# XHSC_HC32L12X register map
Vendor: XHSC Co.Ltd; Series: ARMCM0P; File version: 1.0
CPU: CM0P r0p0, little endian, no MPU, no FPU, 3 interrupt priority bits
Registers are 32-bit, read-write, reset 0x0 unless marked. A register's access mark holds for its fields unless they carry their own. Offsets are from the block's base; [hi:lo] are bit positions; 'fields as' and 'values as' point back to an identical list.

## DEBUG_ACTIVE
Base 0x40021838
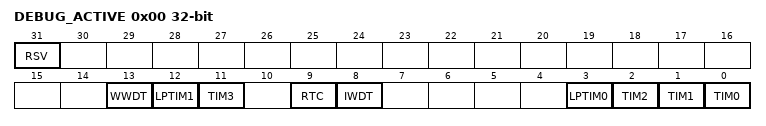
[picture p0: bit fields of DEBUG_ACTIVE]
0x00 DEBUG_ACTIVE (reset mask 0x3B0F)
  [31] RSV, [13] WWDT, [12] LPTIM1, [11] TIM3, [9] RTC, [8] IWDT, [3] LPTIM0, [2] TIM2, [1] TIM1, [0] TIM0

## DMAC
Base 0x40021000
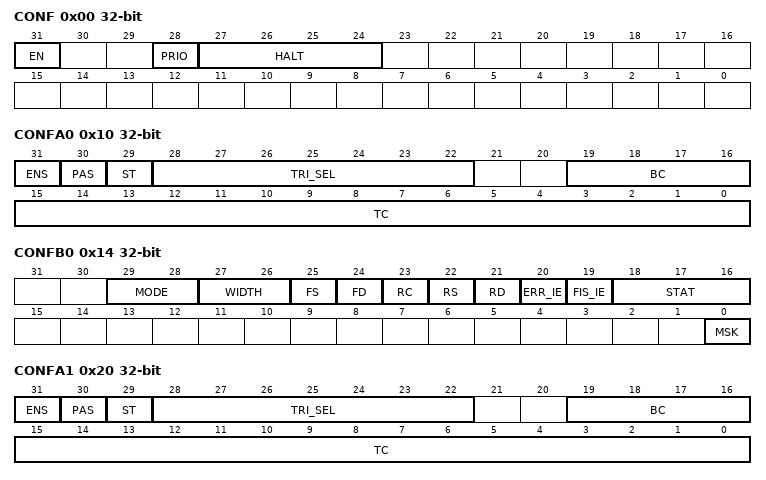
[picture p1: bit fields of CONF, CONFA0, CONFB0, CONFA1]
0x00 CONF
  [31] EN, [28] PRIO, [27:24] HALT
0x10 CONFA0
  [31] ENS, [30] PAS, [29] ST, [28:22] TRI_SEL, [19:16] BC, [15:0] TC
0x14 CONFB0
  [29:28] MODE, [27:26] WIDTH, [25] FS, [24] FD, [23] RC, [22] RS, [21] RD, [20] ERR_IE, [19] FIS_IE, [18:16] STAT, [0] MSK
0x18 SRCADR0
  [31:0] SRCADR
0x1C DSTADR0
  [31:0] DSTADR
0x20 CONFA1
  [31] ENS, [30] PAS, [29] ST, [28:22] TRI_SEL, [19:16] BC, [15:0] TC
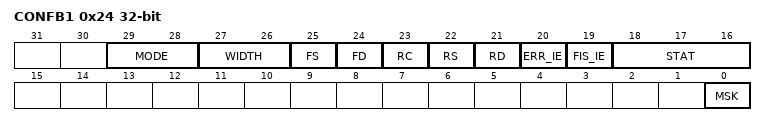
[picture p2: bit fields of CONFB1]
0x24 CONFB1
  fields as CONFB0
0x28 SRCADR
0x2C DSTADR

## FLASH
Base 0x40020000
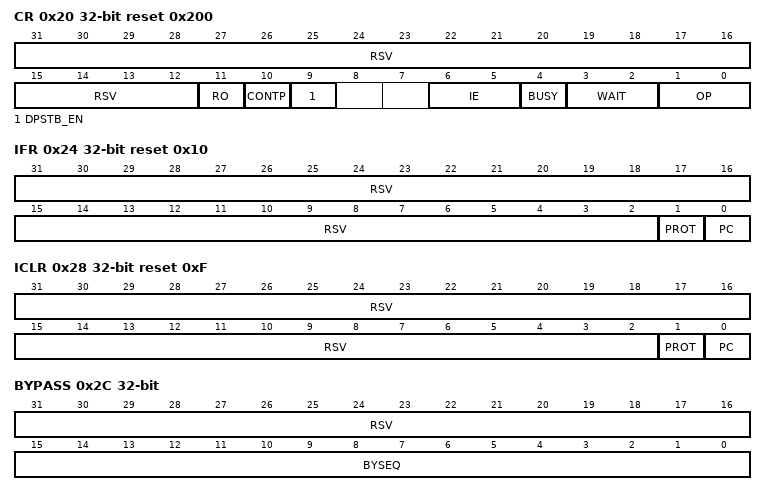
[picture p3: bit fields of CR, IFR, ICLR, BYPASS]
0x20 CR reset 0x200 (reset mask 0xFFF)
  [31:12] RSV, [11] RO, [10] CONTP, [9] DPSTB_EN, [6:5] IE, [4] BUSY ro, [3:2] WAIT, [1:0] OP
0x24 IFR ro reset 0x10 (reset mask 0x3)
  [31:2] RSV, [1] PROT, [0] PC
0x28 ICLR wo reset 0xF (reset mask 0xF)
  [31:2] RSV, [1] PROT, [0] PC
0x2C BYPASS wo (reset mask 0xFFFF)
  [31:16] RSV rw, [15:0] BYSEQ rw
0x30 SLOCK0
  [31:0] SLOCK
0x34 SLOCK1
  [31:0] SLOCK
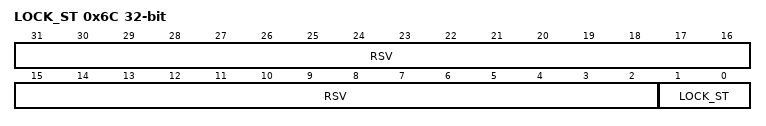
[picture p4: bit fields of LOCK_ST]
0x6C LOCK_ST ro (reset mask 0x3)
  [31:2] RSV rw, [1:0] LOCK_ST

## HSI2C
Base 0x4000BC00
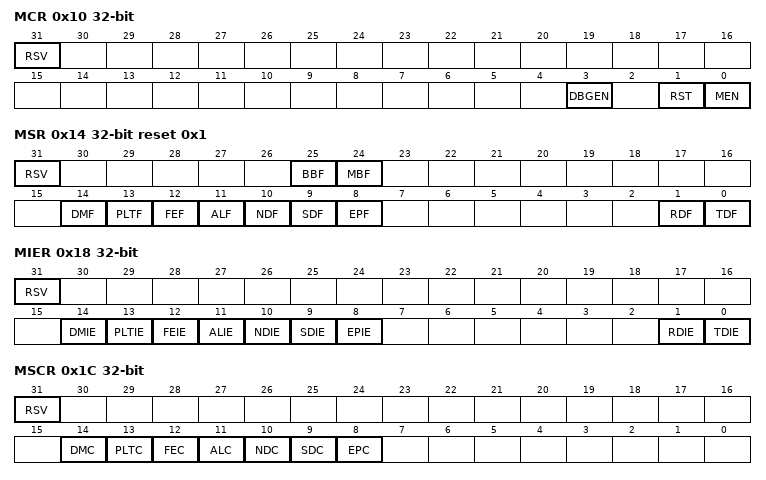
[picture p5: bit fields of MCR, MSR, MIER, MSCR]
0x10 MCR (reset mask 0xF)
  [31] RSV, [3] DBGEN, [1] RST, [0] MEN
0x14 MSR ro reset 0x1 (reset mask 0x0)
  [31] RSV, [25] BBF, [24] MBF, [14] DMF, [13] PLTF, [12] FEF, [11] ALF, [10] NDF, [9] SDF, [8] EPF, [1] RDF, [0] TDF
0x18 MIER (reset mask 0x7F03)
  [31] RSV, [14] DMIE, [13] PLTIE, [12] FEIE, [11] ALIE, [10] NDIE, [9] SDIE, [8] EPIE, [1] RDIE, [0] TDIE
0x1C MSCR (reset mask 0x7F00)
  [31] RSV wo, [14] DMC wo, [13] PLTC wo, [12] FEC wo, [11] ALC wo, [10] NDC wo, [9] SDC wo, [8] EPC wo
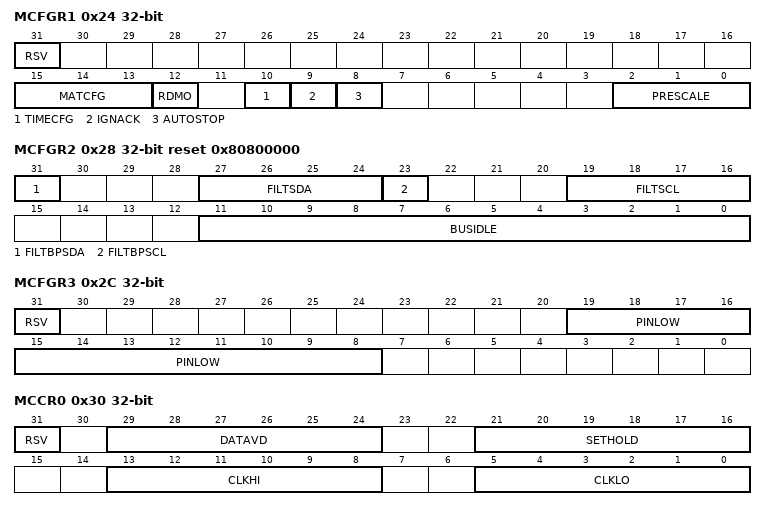
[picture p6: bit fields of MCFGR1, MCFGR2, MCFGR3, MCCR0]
0x24 MCFGR1 (reset mask 0x7070707)
  [31] RSV, [15:13] MATCFG, [12] RDMO, [10] TIMECFG, [9] IGNACK, [8] AUTOSTOP, [2:0] PRESCALE
0x28 MCFGR2 reset 0x80800000
  [31] FILTBPSDA, [27:24] FILTSDA, [23] FILTBPSCL, [19:16] FILTSCL, [11:0] BUSIDLE
0x2C MCFGR3 (reset mask 0xFFF00)
  [31] RSV, [19:8] PINLOW
0x30 MCCR0 (reset mask 0x3F3F3F3F)
  [31] RSV, [29:24] DATAVD, [21:16] SETHOLD, [13:8] CLKHI, [5:0] CLKLO
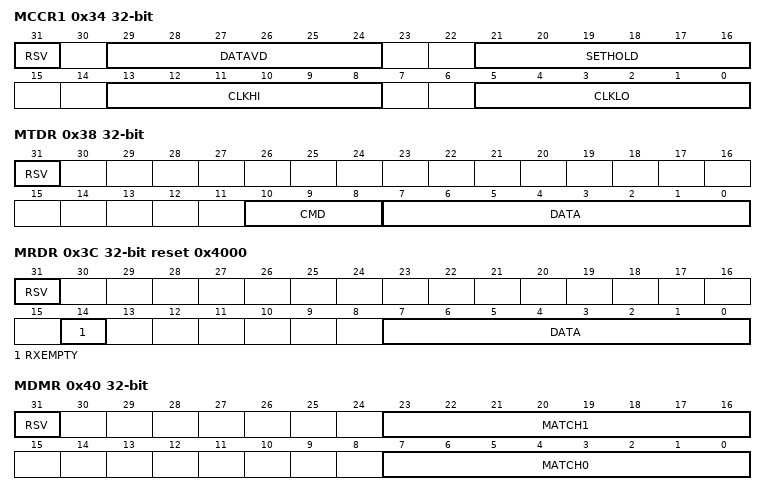
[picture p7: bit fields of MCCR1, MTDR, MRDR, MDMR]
0x34 MCCR1 (reset mask 0x3F3F3F3F)
  [31] RSV, [29:24] DATAVD, [21:16] SETHOLD, [13:8] CLKHI, [5:0] CLKLO
0x38 MTDR wo reset not defined
  [31] RSV, [10:8] CMD, [7:0] DATA
0x3C MRDR ro reset 0x4000 (reset mask 0x0)
  [31] RSV, [14] RXEMPTY, [7:0] DATA
0x40 MDMR (reset mask 0xFF00FF)
  [31] RSV, [23:16] MATCH1, [7:0] MATCH0
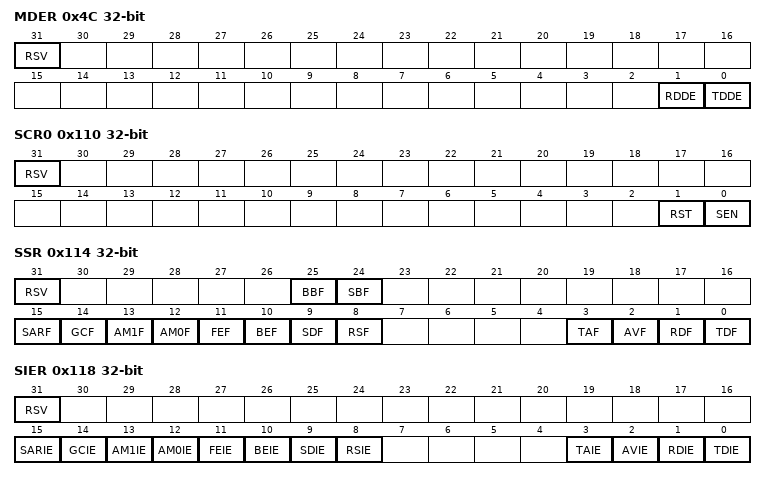
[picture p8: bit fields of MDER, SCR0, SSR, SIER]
0x4C MDER (reset mask 0x3)
  [31] RSV, [1] RDDE, [0] TDDE
0x110 SCR0 (reset mask 0x33)
  [31] RSV ro, [1] RST, [0] SEN
0x114 SSR ro reset not defined
  [31] RSV, [25] BBF, [24] SBF, [15] SARF, [14] GCF, [13] AM1F, [12] AM0F, [11] FEF, [10] BEF, [9] SDF, [8] RSF, [3] TAF, [2] AVF, [1] RDF, [0] TDF
0x118 SIER (reset mask 0xFF0F)
  [31] RSV, [15] SARIE, [14] GCIE, [13] AM1IE, [12] AM0IE, [11] FEIE, [10] BEIE, [9] SDIE, [8] RSIE, [3] TAIE, [2] AVIE, [1] RDIE, [0] TDIE
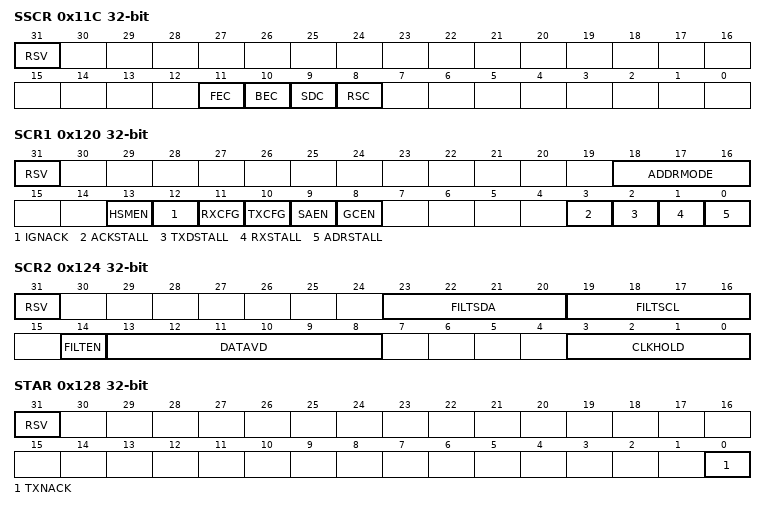
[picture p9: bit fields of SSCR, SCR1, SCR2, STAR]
0x11C SSCR reset not defined
  [31] RSV wo, [11] FEC wo, [10] BEC wo, [9] SDC wo, [8] RSC wo
0x120 SCR1 (reset mask 0x73F0F)
  [31] RSV, [18:16] ADDRMODE, [13] HSMEN, [12] IGNACK, [11] RXCFG, [10] TXCFG, [9] SAEN, [8] GCEN, [3] ACKSTALL, [2] TXDSTALL, [1] RXSTALL, [0] ADRSTALL
0x124 SCR2 (reset mask 0xF0F3F0F)
  [31] RSV, [23:20] FILTSDA, [19:16] FILTSCL, [14] FILTEN, [13:8] DATAVD, [3:0] CLKHOLD
0x128 STAR (reset mask 0x1)
  [31] RSV, [0] TXNACK
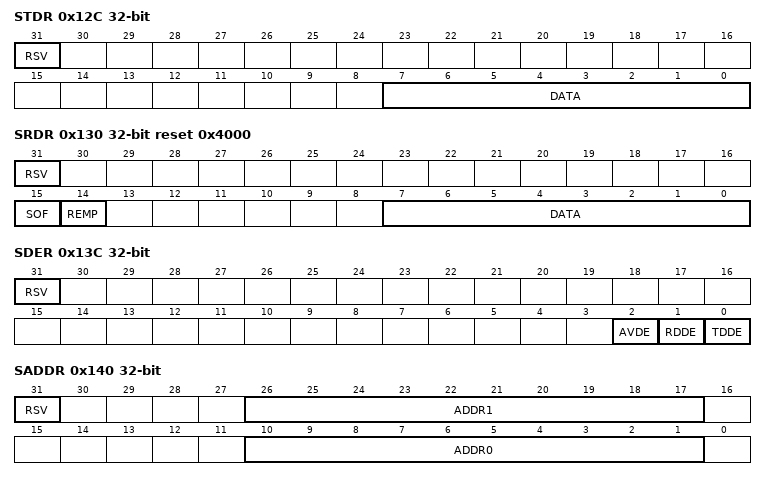
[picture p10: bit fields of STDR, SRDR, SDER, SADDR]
0x12C STDR wo reset not defined
  [31] RSV, [7:0] DATA
0x130 SRDR ro reset 0x4000 (reset mask 0x0)
  [31] RSV, [15] SOF, [14] REMP, [7:0] DATA
0x13C SDER (reset mask 0x7)
  [31] RSV, [2] AVDE, [1] RDDE, [0] TDDE
0x140 SADDR (reset mask 0x7FE07FE)
  [31] RSV, [26:17] ADDR1, [10:1] ADDR0
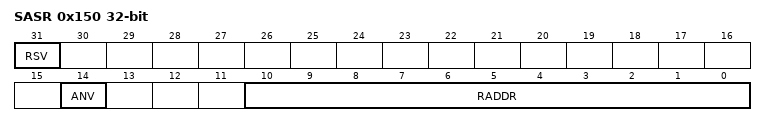
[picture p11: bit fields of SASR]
0x150 SASR ro reset not defined
  [31] RSV, [14] ANV, [10:0] RADDR
